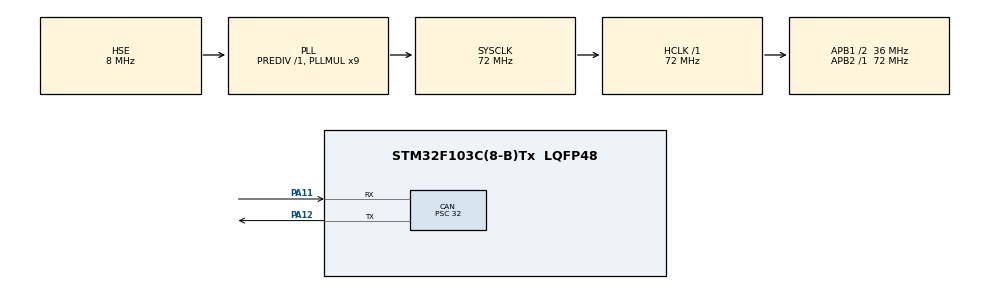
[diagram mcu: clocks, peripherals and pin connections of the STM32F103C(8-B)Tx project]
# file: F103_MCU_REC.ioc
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CAN.ABOM=ENABLE
CAN.AWUM=ENABLE
CAN.BS1=CAN_BS1_2TQ
CAN.BS2=CAN_BS2_2TQ
CAN.CalculateBaudRate=225000
CAN.CalculateTimeBit=4444
CAN.CalculateTimeQuantum=888.8888888888889
CAN.Prescaler=32
Mcu.Family=STM32F1
Mcu.Name=STM32F103C(8-B)Tx
Mcu.Package=LQFP48
NVIC.PriorityGroup=NVIC_PRIORITYGROUP_4
NVIC.USB_HP_CAN1_TX_IRQn=true\:0\:0\:false\:false\:true\:true\:true\:true
NVIC.USB_LP_CAN1_RX0_IRQn=true\:0\:0\:false\:false\:true\:true\:true\:true
PA11.GPIO_PuPd=GPIO_PULLUP
PA11.Mode=CAN_Activate
PA11.Signal=CAN_RX
PA12.Mode=CAN_Activate
PA12.Signal=CAN_TX
PA13.Mode=Serial_Wire
PA13.Signal=SYS_JTMS-SWDIO
PA14.Mode=Serial_Wire
PA14.Signal=SYS_JTCK-SWCLK
PD0-OSC_IN.Mode=HSE-External-Oscillator
PD0-OSC_IN.Signal=RCC_OSC_IN
PD1-OSC_OUT.Mode=HSE-External-Oscillator
PD1-OSC_OUT.Signal=RCC_OSC_OUT
ProjectManager.HeapSize=0x200
ProjectManager.StackSize=0x400
ProjectManager.TargetToolchain=STM32CubeIDE
RCC.AHBFreq_Value=72000000
RCC.APB1CLKDivider=RCC_HCLK_DIV2
RCC.APB1Freq_Value=36000000
RCC.APB1TimFreq_Value=72000000
RCC.APB2Freq_Value=72000000
RCC.APB2TimFreq_Value=72000000
RCC.HCLKFreq_Value=72000000
RCC.PLLMUL=RCC_PLL_MUL9
RCC.PLLSourceVirtual=RCC_PLLSOURCE_HSE
RCC.SYSCLKFreq_VALUE=72000000
RCC.SYSCLKSource=RCC_SYSCLKSOURCE_PLLCLK
RCC.USBFreq_Value=72000000
board=custom

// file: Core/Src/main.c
/* USER CODE BEGIN Header */
/**
  ******************************************************************************
  * @file           : main.c
  * @brief          : Main program body
  ******************************************************************************
  * @attention
  *
  * Copyright (c) 2025 STMicroelectronics.
  * All rights reserved.
  *
  * This software is licensed under terms that can be found in the LICENSE file
  * in the root directory of this software component.
  * If no LICENSE file comes with this software, it is provided AS-IS.
  *
  ******************************************************************************
  */
/* USER CODE END Header */
#include "main.h"

CAN_HandleTypeDef hcan;

void SystemClock_Config(void);
static void MX_GPIO_Init(void);
static void MX_CAN_Init(void);

/* USER CODE BEGIN 0 */
#define MAX_CAN_MSGS 3

typedef struct {
    CAN_RxHeaderTypeDef header;
    uint8_t data[8];
} CAN_Message;

volatile CAN_Message can_one[MAX_CAN_MSGS];
volatile CAN_Message can_two[MAX_CAN_MSGS];
CAN_Message *msg;
volatile uint8_t can_one_head = 0, can_one_tail = 0;
volatile uint8_t can_two_head = 0, can_two_tail = 0;

CAN_TxHeaderTypeDef TxHeader;
uint8_t TxData[8];
uint32_t TxMailbox;

// ==== CAN TX init ====
void CAN_TXinit(void) {
    TxHeader.IDE = CAN_ID_STD;
    TxHeader.StdId = 0x446;
    TxHeader.RTR = CAN_RTR_DATA;
    TxHeader.DLC = 8;
}

// ==== Truyền tin OK ====
void CAN_transmit_succeed(void) {
    TxData[0] = 'O';
    TxData[1] = 'K';
    for (int i = 2; i < 8; i++) TxData[i] = 0;
    HAL_CAN_AddTxMessage(&hcan, &TxHeader, TxData, &TxMailbox);
}

// ==== Truyền tin FAIL ====
void CAN_transmit_Fail(void) {
    TxData[0] = 'N';
    TxData[1] = 'O';
    TxData[2] = 'T';
    TxData[3] = 'O';
    TxData[4] = 'K';
    for (int i = 5; i < 8; i++) TxData[i] = 0;
    HAL_CAN_AddTxMessage(&hcan, &TxHeader, TxData, &TxMailbox);
}

// ==== Cấu hình filter ====
void CAN_ConfigFilter(void) {
    CAN_FilterTypeDef canFilterConfig;
    canFilterConfig.FilterActivation = CAN_FILTER_ENABLE;
    canFilterConfig.FilterBank = 0;
    canFilterConfig.FilterFIFOAssignment = CAN_FILTER_FIFO0;
    canFilterConfig.FilterScale = CAN_FILTERSCALE_32BIT;
    canFilterConfig.FilterMode = CAN_FILTERMODE_IDMASK;
    canFilterConfig.FilterIdHigh = (0x000 << 5);
    canFilterConfig.FilterIdLow = 0x0000;
    canFilterConfig.FilterMaskIdHigh = (0x000 << 5);  // Chấp nhận mọi ID
    canFilterConfig.FilterMaskIdLow = 0x0000;
    canFilterConfig.SlaveStartFilterBank = 14;

    HAL_CAN_ConfigFilter(&hcan, &canFilterConfig);
}

// ==== Khởi tạo nhận ====
void CAN_Receive_Init(void) {
    CAN_ConfigFilter();
    HAL_CAN_Start(&hcan);
    HAL_CAN_ActivateNotification(&hcan, CAN_IT_RX_FIFO0_MSG_PENDING);
}

// ==== Callback khi nhận tin ====
void HAL_CAN_RxFifo0MsgPendingCallback(CAN_HandleTypeDef *hcan) {
    CAN_RxHeaderTypeDef header;
    uint8_t data[8];

    if (HAL_CAN_GetRxMessage(hcan, CAN_RX_FIFO0, &header, data) == HAL_OK) {
        if (header.StdId == 0x111) {
            can_one[can_one_head].header = header;
            memcpy(can_one[can_one_head].data, data, 8);
            can_one_head = (can_one_head + 1) % MAX_CAN_MSGS;
        } else if (header.StdId == 0x222) {
            can_two[can_two_head].header = header;
            memcpy(can_two[can_two_head].data, data, 8);
            can_two_head = (can_two_head + 1) % MAX_CAN_MSGS;
        }
        CAN_transmit_succeed();
    } else {
        CAN_transmit_Fail();
    }
}

// ==== Xử lý nhận CAN theo vòng đệm ====
void CAN_Receive_Loop(void) {
    // Node 1
    if (can_one_tail != can_one_head) {
        msg = &can_one[can_one_tail];
        can_one_tail = (can_one_tail + 1) % MAX_CAN_MSGS;
    }

    // Node 2
    if (can_two_tail != can_two_head) {
    	msg = &can_two[can_two_tail];
        // Xử lý dữ liệu tại đây
        can_two_tail = (can_two_tail + 1) % MAX_CAN_MSGS;
    }
}
/* USER CODE END 0 */

int main(void)
{

  /* MCU Configuration--------------------------------------------------------*/

  /* Reset of all peripherals, Initializes the Flash interface and the Systick. */
  HAL_Init();

  /* Configure the system clock */
  SystemClock_Config();

  /* Initialize all configured peripherals */
  MX_GPIO_Init();
  MX_CAN_Init();
  /* USER CODE BEGIN 2 */
  CAN_Receive_Init();
  CAN_TXinit();
  /* USER CODE END 2 */

  /* Infinite loop */
  /* USER CODE BEGIN WHILE */
  while (1)
  {
	  CAN_Receive_Loop();
    /* USER CODE END WHILE */

  }
}

void SystemClock_Config(void)
{
  RCC_OscInitTypeDef RCC_OscInitStruct = {0};
  RCC_ClkInitTypeDef RCC_ClkInitStruct = {0};

  /** Initializes the RCC Oscillators according to the specified parameters
  * in the RCC_OscInitTypeDef structure.
  */
  RCC_OscInitStruct.OscillatorType = RCC_OSCILLATORTYPE_HSE;
  RCC_OscInitStruct.HSEState = RCC_HSE_ON;
  RCC_OscInitStruct.HSEPredivValue = RCC_HSE_PREDIV_DIV1;
  RCC_OscInitStruct.HSIState = RCC_HSI_ON;
  RCC_OscInitStruct.PLL.PLLState = RCC_PLL_ON;
  RCC_OscInitStruct.PLL.PLLSource = RCC_PLLSOURCE_HSE;
  RCC_OscInitStruct.PLL.PLLMUL = RCC_PLL_MUL9;
  if (HAL_RCC_OscConfig(&RCC_OscInitStruct) != HAL_OK)
  {
    Error_Handler();
  }

  /** Initializes the CPU, AHB and APB buses clocks
  */
  RCC_ClkInitStruct.ClockType = RCC_CLOCKTYPE_HCLK|RCC_CLOCKTYPE_SYSCLK
                              |RCC_CLOCKTYPE_PCLK1|RCC_CLOCKTYPE_PCLK2;
  RCC_ClkInitStruct.SYSCLKSource = RCC_SYSCLKSOURCE_PLLCLK;
  RCC_ClkInitStruct.AHBCLKDivider = RCC_SYSCLK_DIV1;
  RCC_ClkInitStruct.APB1CLKDivider = RCC_HCLK_DIV2;
  RCC_ClkInitStruct.APB2CLKDivider = RCC_HCLK_DIV1;

  if (HAL_RCC_ClockConfig(&RCC_ClkInitStruct, FLASH_LATENCY_2) != HAL_OK)
  {
    Error_Handler();
  }
}

static void MX_CAN_Init(void)
{

  hcan.Instance = CAN1;
  hcan.Init.Prescaler = 32;
  hcan.Init.Mode = CAN_MODE_NORMAL;
  hcan.Init.SyncJumpWidth = CAN_SJW_1TQ;
  hcan.Init.TimeSeg1 = CAN_BS1_2TQ;
  hcan.Init.TimeSeg2 = CAN_BS2_2TQ;
  hcan.Init.TimeTriggeredMode = DISABLE;
  hcan.Init.AutoBusOff = ENABLE;
  hcan.Init.AutoWakeUp = ENABLE;
  hcan.Init.AutoRetransmission = DISABLE;
  hcan.Init.ReceiveFifoLocked = DISABLE;
  hcan.Init.TransmitFifoPriority = DISABLE;
  if (HAL_CAN_Init(&hcan) != HAL_OK)
  {
    Error_Handler();
  }

}

static void MX_GPIO_Init(void)
{

  /* GPIO Ports Clock Enable */
  __HAL_RCC_GPIOD_CLK_ENABLE();
  __HAL_RCC_GPIOA_CLK_ENABLE();

}

void Error_Handler(void)
{
  __disable_irq();
  while (1)
  {
  }
}
